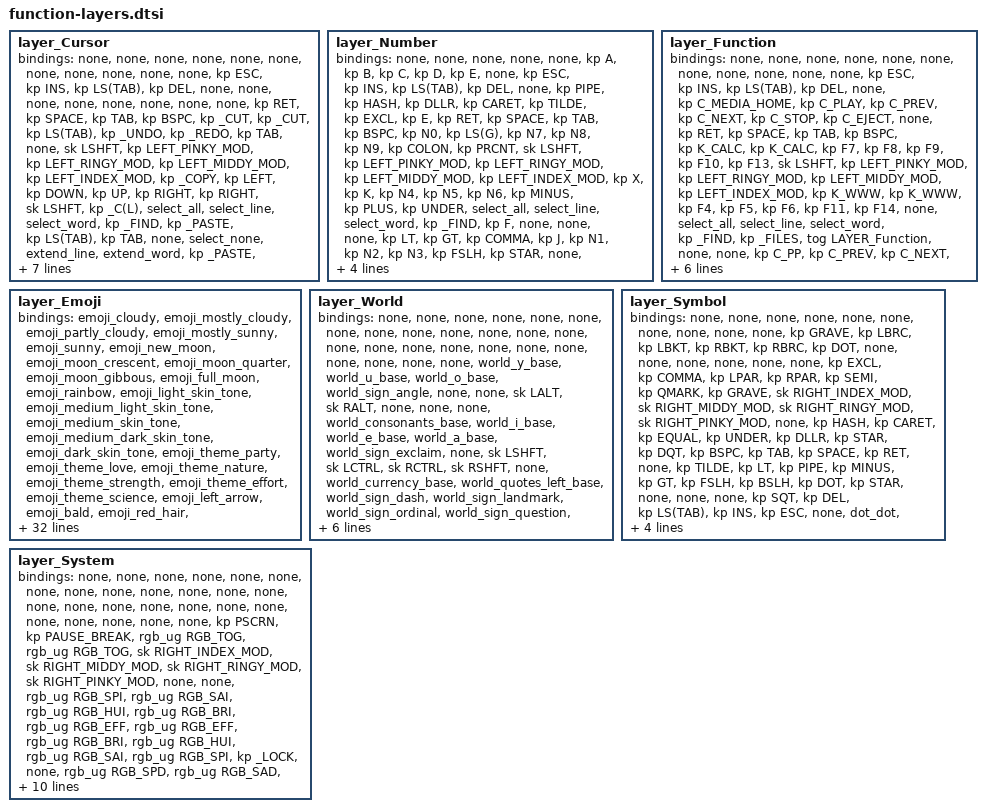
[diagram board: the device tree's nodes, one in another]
        layer_Cursor {
            bindings = <
     &none               &none               &none               &none               &none                                                                                                              &none           &none           &none          &none      &none
     &none             &kp ESC             &kp INS         &kp LS(TAB)             &kp DEL       &none                                                                                     &none        &none           &none           &none          &none      &none
     &none             &kp RET           &kp SPACE             &kp TAB            &kp BSPC    &kp _CUT                                                                                  &kp _CUT  &kp LS(TAB)       &kp _UNDO       &kp _REDO        &kp TAB      &none
 &sk LSHFT  &kp LEFT_PINKY_MOD  &kp LEFT_RINGY_MOD  &kp LEFT_MIDDY_MOD  &kp LEFT_INDEX_MOD   &kp _COPY                                                                                  &kp LEFT     &kp DOWN          &kp UP       &kp RIGHT      &kp RIGHT  &sk LSHFT
 &kp _C(L)         &select_all        &select_line        &select_word           &kp _FIND  &kp _PASTE        &kp LS(TAB)  &kp TAB   &none  &select_none  &extend_line  &extend_word  &kp _PASTE    &kp _HOME       &kp PG_UP       &kp PG_DN       &kp _END  &kp _C(L)
 &kp _C(K)           &kp _UNDO           &kp _REDO      &kp _FIND_PREV      &kp _FIND_NEXT              &tog LAYER_Cursor    &none   &none   &select_all  &select_line  &select_word                &kp _FIND  &kp _FIND_PREV  &kp _FIND_NEXT  &kp LG(LA(F))  &kp _C(K)
            >;
        };

        layer_Number {
            bindings = <
     &none               &none               &none               &none               &none                                                                                          &kp A     &kp B      &kp C      &kp D      &kp E
     &none             &kp ESC             &kp INS         &kp LS(TAB)             &kp DEL   &none                                                                     &kp PIPE  &kp HASH  &kp DLLR  &kp CARET  &kp TILDE   &kp EXCL
     &kp E             &kp RET           &kp SPACE             &kp TAB            &kp BSPC  &kp N0                                                                    &kp LS(G)    &kp N7    &kp N8     &kp N9  &kp COLON  &kp PRCNT
 &sk LSHFT  &kp LEFT_PINKY_MOD  &kp LEFT_RINGY_MOD  &kp LEFT_MIDDY_MOD  &kp LEFT_INDEX_MOD   &kp X                                                                        &kp K    &kp N4    &kp N5     &kp N6  &kp MINUS   &kp PLUS
 &kp UNDER         &select_all        &select_line        &select_word           &kp _FIND   &kp F   &none              &none   &none     &kp LT   &kp GT  &kp COMMA      &kp J    &kp N1    &kp N2     &kp N3   &kp FSLH   &kp STAR
     &none           &kp _UNDO           &kp _REDO      &kp _FIND_PREV      &kp _FIND_NEXT           &none  &tog LAYER_Number   &none  &kp EQUAL  &kp DOT     &kp N0             &kp LPAR  &kp LBKT   &kp RBKT   &kp RPAR     &kp AT
            >;
        };

        layer_Function {
            bindings = <
     &none               &none               &none               &none               &none                                                                                                                     &none         &none         &none          &none           &none
     &none             &kp ESC             &kp INS         &kp LS(TAB)             &kp DEL       &none                                                                               &kp C_MEDIA_HOME     &kp C_PLAY    &kp C_PREV    &kp C_NEXT     &kp C_STOP     &kp C_EJECT
     &none             &kp RET           &kp SPACE             &kp TAB            &kp BSPC  &kp K_CALC                                                                                     &kp K_CALC         &kp F7        &kp F8        &kp F9        &kp F10         &kp F13
 &sk LSHFT  &kp LEFT_PINKY_MOD  &kp LEFT_RINGY_MOD  &kp LEFT_MIDDY_MOD  &kp LEFT_INDEX_MOD   &kp K_WWW                                                                                      &kp K_WWW         &kp F4        &kp F5        &kp F6        &kp F11         &kp F14
     &none         &select_all        &select_line        &select_word           &kp _FIND  &kp _FILES  &tog LAYER_Function   &none   &none    &kp C_PP    &kp C_PREV    &kp C_NEXT        &kp _FILES         &kp F1        &kp F2        &kp F3        &kp F12         &kp F15
     &none           &kp _UNDO           &kp _REDO      &kp _FIND_PREV      &kp _FIND_NEXT                            &none   &none   &none  &kp C_MUTE  &kp C_VOL_DN  &kp C_VOL_UP                    &kp C_BRI_MAX  &kp C_BRI_UP  &kp C_BRI_DN  &kp C_BRI_MIN  &kp C_BRI_AUTO
            >;
        };

        layer_Emoji {
            bindings = <
     &emoji_cloudy      &emoji_mostly_cloudy           &emoji_partly_cloudy        &emoji_mostly_sunny                  &emoji_sunny                                                                                                                                                                                                      &emoji_new_moon      &emoji_moon_crescent         &emoji_moon_quarter         &emoji_moon_gibbous        &emoji_full_moon
   &emoji_rainbow     &emoji_light_skin_tone  &emoji_medium_light_skin_tone    &emoji_medium_skin_tone  &emoji_medium_dark_skin_tone  &emoji_dark_skin_tone                                                                                                                                                &emoji_theme_party           &emoji_theme_love       &emoji_theme_nature       &emoji_theme_strength         &emoji_theme_effort    &emoji_theme_science
 &emoji_left_arrow               &emoji_bald                &emoji_red_hair          &emoji_curly_hair             &emoji_white_hair     &emoji_right_arrow                                                                                                                                                 &emoji_face_laugh           &emoji_face_smile          &emoji_face_eyes            &emoji_face_joke            &emoji_face_fear    &emoji_face_surprise
  &emoji_male_sign  &emoji_hair_style_preset        &emoji_skin_tone_preset  &emoji_gender_sign_preset                     &sk LSHFT     &emoji_female_sign                                                                                                                                          &emoji_gesture_attention     &emoji_gesture_approval  &emoji_gesture_gratitude      &emoji_gesture_anxiety      &emoji_gesture_despair  &emoji_gesture_curious
    &emoji_old_man                &emoji_man                     &emoji_boy                &emoji_girl                  &emoji_woman       &emoji_old_woman  &emoji_cityscape  &emoji_cityscape_dusk    &emoji_cityscape_night    &emoji_theme_magic    &emoji_theme_space   &emoji_theme_awesome  &emoji_person_tipping_hand  &emoji_person_gesturing_ok      &emoji_person_bowing  &emoji_person_raising_hand  &emoji_person_gesturing_no       &emoji_theme_sigh
 &emoji_theme_game        &emoji_theme_trend                    &emoji_baby         &emoji_baby_bottle              &tog LAYER_Emoji                               &emoji_zwj         &emoji_sunrise  &emoji_sunrise_mountains  &emoji_gesture_hands  &emoji_gesture_point  &emoji_gesture_thumbs                                            &emoji_check                &emoji_100              &emoji_warning                &emoji_cross         &emoji_question
            >;
        };

        layer_World {
            bindings = <
                &none                     &none             &none                 &none                &none                                                                                           &none      &none      &none      &none   &none
                &none                     &none             &none                 &none                &none                 &none                                                   &none             &none      &none      &none      &none   &none
                &none                     &none     &world_y_base         &world_u_base        &world_o_base     &world_sign_angle                                                   &none             &none   &sk LALT   &sk RALT      &none   &none
                &none    &world_consonants_base     &world_i_base         &world_e_base        &world_a_base   &world_sign_exclaim                                                   &none         &sk LSHFT  &sk LCTRL  &sk RCTRL  &sk RSHFT   &none
 &world_currency_base   &world_quotes_left_base  &world_sign_dash  &world_sign_landmark  &world_sign_ordinal  &world_sign_question   &none   &none   &none   &none   &none   &none   &none             &none      &none      &none      &none   &none
     &world_sign_base  &world_quotes_right_base             &none                 &none                &none                         &none   &none   &none   &none   &none   &none          &tog LAYER_World      &none      &none      &none   &none
            >;
        };

        layer_Symbol {
            bindings = <
     &none      &none      &none      &none     &none                                                                                                         &none                &none                &none                &none   &none
 &kp GRAVE   &kp LBRC   &kp LBKT   &kp RBKT  &kp RBRC    &kp DOT                                                                         &none                &none                &none                &none                &none   &none
  &kp EXCL  &kp COMMA   &kp LPAR   &kp RPAR  &kp SEMI  &kp QMARK                                                                     &kp GRAVE  &sk RIGHT_INDEX_MOD  &sk RIGHT_MIDDY_MOD  &sk RIGHT_RINGY_MOD  &sk RIGHT_PINKY_MOD   &none
  &kp HASH  &kp CARET  &kp EQUAL  &kp UNDER  &kp DLLR   &kp STAR                                                                       &kp DQT             &kp BSPC              &kp TAB            &kp SPACE              &kp RET   &none
 &kp TILDE     &kp LT   &kp PIPE  &kp MINUS    &kp GT   &kp FSLH   &kp BSLH    &kp DOT  &kp STAR   &none   &none              &none    &kp SQT              &kp DEL          &kp LS(TAB)              &kp INS              &kp ESC   &none
  &dot_dot   &kp AMPS    &kp SQT    &kp DQT  &kp PLUS             &kp PRCNT  &kp COLON    &kp AT   &none   &none  &tog LAYER_Symbol                           &none                &none                &none                &none   &none
            >;
        };

        layer_System {
            bindings = <
  &none            &none            &none            &none               &none                                                                                                                           &none                &none                &none                &none       &none
  &none            &none            &none            &none               &none            &none                                                                                     &none                &none                &none                &none                &none       &none
  &none            &none            &none        &kp PSCRN     &kp PAUSE_BREAK  &rgb_ug RGB_TOG                                                                           &rgb_ug RGB_TOG  &sk RIGHT_INDEX_MOD  &sk RIGHT_MIDDY_MOD  &sk RIGHT_RINGY_MOD  &sk RIGHT_PINKY_MOD       &none
  &none  &rgb_ug RGB_SPI  &rgb_ug RGB_SAI  &rgb_ug RGB_HUI     &rgb_ug RGB_BRI  &rgb_ug RGB_EFF                                                                           &rgb_ug RGB_EFF      &rgb_ug RGB_BRI      &rgb_ug RGB_HUI      &rgb_ug RGB_SAI      &rgb_ug RGB_SPI   &kp _LOCK
  &none  &rgb_ug RGB_SPD  &rgb_ug RGB_SAD  &rgb_ug RGB_HUD     &rgb_ug RGB_BRD  &rgb_ug RGB_EFR  &kp _LOCK  &kp _SLEEP  &kp _POWER   &none      &none  &tog LAYER_System  &rgb_ug RGB_EFR      &rgb_ug RGB_BRD      &rgb_ug RGB_HUD      &rgb_ug RGB_SAD      &rgb_ug RGB_SPD  &kp _SLEEP
  &none            &none            &none            &none  &linux_magic_sysrq                    &kp SLCK  &kp KP_NUM    &kp CAPS   &none  &kp PSCRN    &kp PAUSE_BREAK                    &linux_magic_sysrq             &kp SLCK           &kp KP_NUM             &kp CAPS  &kp _POWER
            >;
        };
